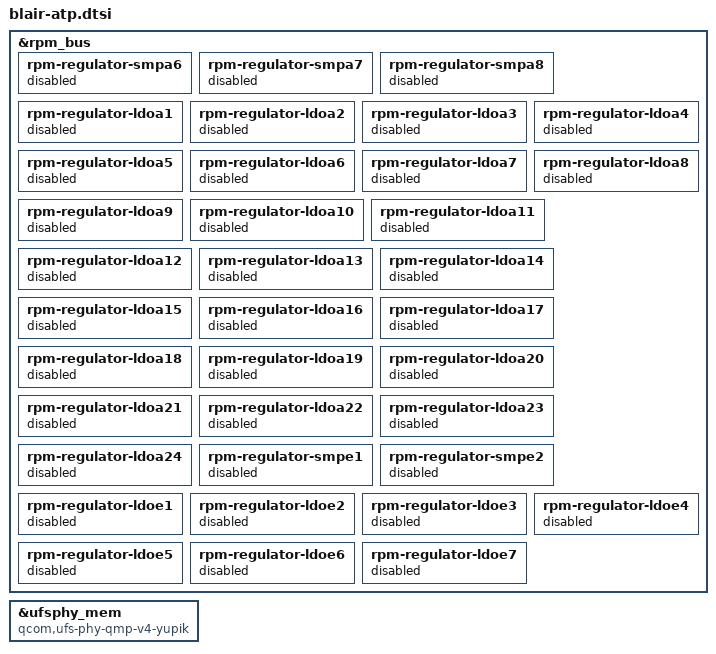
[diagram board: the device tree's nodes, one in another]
&rpm_bus {
	/* Delete all PM6125 and PMR735a rpm-regulators */
	/delete-node/ rpm-regulator-smpa6;
	/delete-node/ rpm-regulator-smpa7;
	/delete-node/ rpm-regulator-smpa8;
	/delete-node/ rpm-regulator-ldoa1;
	/delete-node/ rpm-regulator-ldoa2;
	/delete-node/ rpm-regulator-ldoa3;
	/delete-node/ rpm-regulator-ldoa4;
	/delete-node/ rpm-regulator-ldoa5;
	/delete-node/ rpm-regulator-ldoa6;
	/delete-node/ rpm-regulator-ldoa7;
	/delete-node/ rpm-regulator-ldoa8;
	/delete-node/ rpm-regulator-ldoa9;
	/delete-node/ rpm-regulator-ldoa10;
	/delete-node/ rpm-regulator-ldoa11;
	/delete-node/ rpm-regulator-ldoa12;
	/delete-node/ rpm-regulator-ldoa13;
	/delete-node/ rpm-regulator-ldoa14;
	/delete-node/ rpm-regulator-ldoa15;
	/delete-node/ rpm-regulator-ldoa16;
	/delete-node/ rpm-regulator-ldoa17;
	/delete-node/ rpm-regulator-ldoa18;
	/delete-node/ rpm-regulator-ldoa19;
	/delete-node/ rpm-regulator-ldoa20;
	/delete-node/ rpm-regulator-ldoa21;
	/delete-node/ rpm-regulator-ldoa22;
	/delete-node/ rpm-regulator-ldoa23;
	/delete-node/ rpm-regulator-ldoa24;

	/delete-node/ rpm-regulator-smpe1;
	/delete-node/ rpm-regulator-smpe2;
	/delete-node/ rpm-regulator-ldoe1;
	/delete-node/ rpm-regulator-ldoe2;
	/delete-node/ rpm-regulator-ldoe3;
	/delete-node/ rpm-regulator-ldoe4;
	/delete-node/ rpm-regulator-ldoe5;
	/delete-node/ rpm-regulator-ldoe7;

	/* Disable all PM6125 and PMR735a rpm-regulators */
	rpm-regulator-smpa6 {
		status = "disabled";
	};

	rpm-regulator-smpa7 {
		status = "disabled";
	};

	rpm-regulator-smpa8 {
		status = "disabled";
	};

	rpm-regulator-ldoa1 {
		status = "disabled";
	};

	rpm-regulator-ldoa2 {
		status = "disabled";
	};

	rpm-regulator-ldoa3 {
		status = "disabled";
	};

	rpm-regulator-ldoa4 {
		status = "disabled";
	};

	rpm-regulator-ldoa5 {
		status = "disabled";
	};

	rpm-regulator-ldoa6 {
		status = "disabled";
	};

	rpm-regulator-ldoa7 {
		status = "disabled";
	};

	rpm-regulator-ldoa8 {
		status = "disabled";
	};

	rpm-regulator-ldoa9 {
		status = "disabled";
	};

	rpm-regulator-ldoa10 {
		status = "disabled";
	};

	rpm-regulator-ldoa11 {
		status = "disabled";
	};

	rpm-regulator-ldoa12 {
		status = "disabled";
	};

	rpm-regulator-ldoa13 {
		status = "disabled";
	};

	rpm-regulator-ldoa14 {
		status = "disabled";
	};

	rpm-regulator-ldoa15 {
		status = "disabled";
	};

	rpm-regulator-ldoa16 {
		status = "disabled";
	};

	rpm-regulator-ldoa17 {
		status = "disabled";
	};

	rpm-regulator-ldoa18 {
		status = "disabled";
	};

	rpm-regulator-ldoa19 {
		status = "disabled";
	};

	rpm-regulator-ldoa20 {
		status = "disabled";
	};

	rpm-regulator-ldoa21 {
		status = "disabled";
	};

	rpm-regulator-ldoa22 {
		status = "disabled";
	};

	rpm-regulator-ldoa23 {
		status = "disabled";
	};

	rpm-regulator-ldoa24 {
		status = "disabled";
	};

	rpm-regulator-smpe1 {
		status = "disabled";
	};

	rpm-regulator-smpe2 {
		status = "disabled";
	};

	rpm-regulator-ldoe1 {
		status = "disabled";
	};

	rpm-regulator-ldoe2 {
		status = "disabled";
	};

	rpm-regulator-ldoe3 {
		status = "disabled";
	};

	rpm-regulator-ldoe4 {
		status = "disabled";
	};

	rpm-regulator-ldoe5 {
		status = "disabled";
	};

	rpm-regulator-ldoe6 {
		status = "disabled";
	};

	rpm-regulator-ldoe7 {
		status = "disabled";
	};
};

&ufsphy_mem {
	compatible = "qcom,ufs-phy-qmp-v4-yupik";
};

#include "pm6350-rpm-regulator.dtsi"
#include "pm6150l-rpm-regulator.dtsi"
#include "holi-regulators-pm6350.dtsi"

#include "holi-atp.dtsi"
